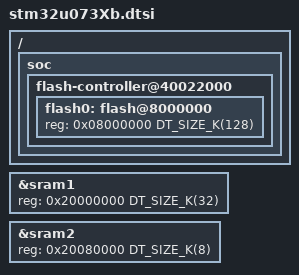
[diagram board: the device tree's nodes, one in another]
/*
 * Copyright (c) 2024 STMicroelectronics
 *
 * SPDX-License-Identifier: Apache-2.0
 */
#include <st/u0/stm32u073.dtsi>

/ {
	soc {
		flash-controller@40022000 {
			flash0: flash@8000000 {
				reg = <0x08000000 DT_SIZE_K(128)>;
			};
		};
	};
};

&sram1 {
	reg = <0x20000000 DT_SIZE_K(32)>;
};

&sram2 {
	reg = <0x20080000 DT_SIZE_K(8)>;
};
